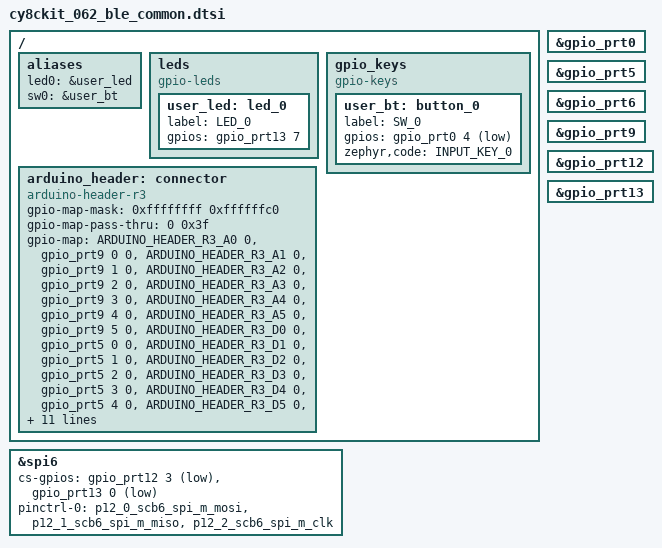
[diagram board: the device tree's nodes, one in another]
/*
 * Copyright (c) 2021, ATL Electronics
 *
 * SPDX-License-Identifier: Apache-2.0
 */

#include <zephyr/dt-bindings/gpio/arduino-header-r3.h>
#include <zephyr/dt-bindings/input/input-event-codes.h>

/ {
	aliases {
		led0 = &user_led;
		sw0 = &user_bt;
	};

	leds {
		compatible = "gpio-leds";

		user_led: led_0 {
			label = "LED_0";
			gpios = <&gpio_prt13 7 GPIO_ACTIVE_HIGH>;
		};
	};

	gpio_keys {
		compatible = "gpio-keys";

		user_bt: button_0 {
			label = "SW_0";
			gpios = <&gpio_prt0 4 (GPIO_PULL_UP | GPIO_ACTIVE_LOW)>;
			zephyr,code = <INPUT_KEY_0>;
		};
	};

	arduino_header: connector {
		compatible = "arduino-header-r3";
		#gpio-cells = <2>;
		gpio-map-mask = <0xffffffff 0xffffffc0>;
		gpio-map-pass-thru = <0 0x3f>;				/*       shared */
		gpio-map = <ARDUINO_HEADER_R3_A0 0 &gpio_prt9 0 0>,
			   <ARDUINO_HEADER_R3_A1 0 &gpio_prt9 1 0>,
			   <ARDUINO_HEADER_R3_A2 0 &gpio_prt9 2 0>,
			   <ARDUINO_HEADER_R3_A3 0 &gpio_prt9 3 0>,
			   <ARDUINO_HEADER_R3_A4 0 &gpio_prt9 4 0>,
			   <ARDUINO_HEADER_R3_A5 0 &gpio_prt9 5 0>,
			   <ARDUINO_HEADER_R3_D0 0 &gpio_prt5 0 0>,	/* RX-5         */
			   <ARDUINO_HEADER_R3_D1 0 &gpio_prt5 1 0>,	/* TX-5         */
			   <ARDUINO_HEADER_R3_D2 0 &gpio_prt5 2 0>,	/* RTS-5        */
			   <ARDUINO_HEADER_R3_D3 0 &gpio_prt5 3 0>,	/* CTS-5        */
			   <ARDUINO_HEADER_R3_D4 0 &gpio_prt5 4 0>,
			   <ARDUINO_HEADER_R3_D5 0 &gpio_prt5 5 0>,
			   <ARDUINO_HEADER_R3_D6 0 &gpio_prt5 6 0>,
			   <ARDUINO_HEADER_R3_D7 0 &gpio_prt0 2 0>,
			   <ARDUINO_HEADER_R3_D8 0 &gpio_prt13 0 0>,	/* RX-6       y */
			   <ARDUINO_HEADER_R3_D9 0 &gpio_prt13 1 0>,	/* TX-6       y */
			   <ARDUINO_HEADER_R3_D10 0 &gpio_prt12 3 0>,	/* SPI6_SEL0  y */
			   <ARDUINO_HEADER_R3_D11 0 &gpio_prt12 0 0>,	/* SPI6_MOSI  y */
			   <ARDUINO_HEADER_R3_D12 0 &gpio_prt12 1 0>,	/* SPI6_MISO  y */
			   <ARDUINO_HEADER_R3_D13 0 &gpio_prt12 2 0>,	/* SPI6_CLK   y */
			   <ARDUINO_HEADER_R3_D14 0 &gpio_prt6 1 0>,	/* SDAx         */
			   <ARDUINO_HEADER_R3_D15 0 &gpio_prt6 0 0>;	/* SCLx         */
	};
};

&gpio_prt0 {
	status = "okay";
};

&gpio_prt5 {
	status = "okay";
};

&gpio_prt6 {
	status = "okay";
};

&gpio_prt9 {
	status = "okay";
};

&gpio_prt12 {
	status = "okay";
};

&gpio_prt13 {
	status = "okay";
};

&spi6 {
	cs-gpios = <&gpio_prt12 3 (GPIO_ACTIVE_LOW | GPIO_PULL_UP)>,
		   <&gpio_prt13 0 (GPIO_ACTIVE_LOW | GPIO_PULL_UP)>;

	pinctrl-0 = <&p12_0_scb6_spi_m_mosi &p12_1_scb6_spi_m_miso &p12_2_scb6_spi_m_clk>;
	pinctrl-names = "default";
};
